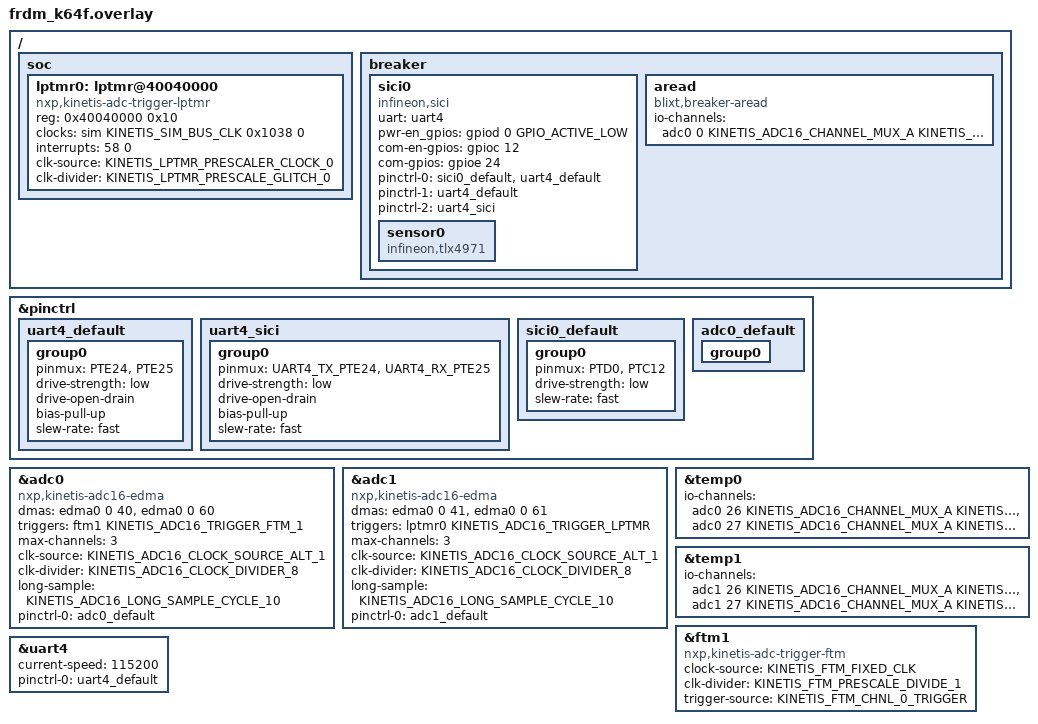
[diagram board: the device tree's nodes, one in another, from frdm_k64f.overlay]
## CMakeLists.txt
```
cmake_minimum_required(VERSION 3.20.0)

find_package(Zephyr REQUIRED HINTS $ENV{ZEPHYR_BASE})

project(tli4971)
add_subdirectory(src)
```

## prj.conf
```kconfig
# Heap and stack size settings
CONFIG_HEAP_MEM_POOL_SIZE=2048
CONFIG_MAIN_STACK_SIZE=2048
CONFIG_SYSTEM_WORKQUEUE_STACK_SIZE=2048

# Stack analysis settings
CONFIG_STACK_SENTINEL=y
CONFIG_STACK_USAGE=y
CONFIG_INIT_STACKS=y

# Thread settings
CONFIG_THREAD_MONITOR=n
CONFIG_THREAD_NAME=y

# Shells
CONFIG_SHELL=y
CONFIG_ADC_SHELL=n
CONFIG_KERNEL_SHELL=y
CONFIG_DEVICE_SHELL=y
CONFIG_SHELL_BACKENDS=y

# Network settings
CONFIG_NETWORKING=y
CONFIG_NET_LOG=y
CONFIG_NET_IPV6=n
CONFIG_NET_IPV4=y
CONFIG_NET_DHCPV4=y
CONFIG_NET_UDP=y
CONFIG_NET_TCP=y
CONFIG_NET_STATISTICS=y
CONFIG_NET_SOCKETS=y
CONFIG_NET_SOCKETS_POSIX_NAMES=y
CONFIG_NET_CONNECTION_MANAGER=y
CONFIG_NET_MGMT=y
CONFIG_NET_MGMT_EVENT=y
CONFIG_NET_CONFIG_AUTO_INIT=n
CONFIG_NET_SHELL=y
CONFIG_NET_MAX_CONN=10

# MCU manager settings
CONFIG_MCUMGR=y
CONFIG_MCUMGR_GRP_IMG=y
CONFIG_MCUMGR_GRP_OS=y
CONFIG_MCUMGR_TRANSPORT_UDP=y
CONFIG_MCUMGR_TRANSPORT_UDP_IPV4=y
CONFIG_MCUMGR_TRANSPORT_UDP_IPV6=n

# CoAP settings
CONFIG_COAP=y
CONFIG_COAP_WELL_KNOWN_BLOCK_WISE=n

# Other settings
CONFIG_PRINTK=y
CONFIG_LOG=y
CONFIG_BOOT_BANNER=y
CONFIG_FLASH=y
CONFIG_BOOTLOADER_MCUBOOT=y

CONFIG_NEWLIB_LIBC=y
CONFIG_CMSIS_DSP=y
CONFIG_CMSIS_DSP_FASTMATH=y

CONFIG_NANOPB=y
CONFIG_ZERO_CONTROL_MESSAGES=y

CONFIG_TIMING_FUNCTIONS=y

# Additional drivers
CONFIG_SICI=y
CONFIG_TLX4971=y
CONFIG_TLX4971_SHELL=y
```

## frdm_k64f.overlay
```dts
#include <dt-bindings/adc/kinetis-adc.h>
#include <dt-bindings/timer/kinetis-lptmr.h>
#include <dt-bindings/timer/kinetis-ftm.h>

/ {
	soc {
		/* LPTMR is not in nxp_k6x.dtsi. */
		lptmr0: lptmr@40040000 {
			compatible = "nxp,kinetis-adc-trigger-lptmr";
			reg = <0x40040000 0x10>;
			clocks = <&sim KINETIS_SIM_BUS_CLK 0x1038 0>;
			interrupts = <58 0>;
			clk-source = <KINETIS_LPTMR_PRESCALER_CLOCK_0>; /* MCGIRCLK */
			clk-divider = <KINETIS_LPTMR_PRESCALE_GLITCH_0>; /* divide by 2 */
			#trigger-cells = <1>;
		};
	};

	breaker {
		sici0: sici0 {
			compatible = "infineon,sici";
			uart = <&uart4>;
			pwr-en_gpios = <&gpiod 0 GPIO_ACTIVE_LOW>;
			com-en-gpios = <&gpioc 12 GPIO_ACTIVE_HIGH>;
			com-gpios = <&gpioe 24 GPIO_ACTIVE_HIGH>;
			pinctrl-0 = <&sici0_default &uart4_default>;
			pinctrl-1 = <&uart4_default>;
			pinctrl-2 = <&uart4_sici>;
			pinctrl-names = "default", "activation", "communication";
			status = "okay";

			sensor0: sensor0 {
				compatible = "infineon,tlx4971";
				status = "okay";
			};
		};

		aread: aread {
			compatible = "blixt,breaker-aread";
			io-channels = <&adc0 0 KINETIS_ADC16_CHANNEL_MUX_A KINETIS_ADC16_CHANNEL_TYPE_DF>; /* I_MAINS */
			io-channel-names = "I_MAINS";
		};
	};
};

&pinctrl {
	uart4_default: uart4_default {
		group0 {
			pinmux = <PTE24>,
				<PTE25>;
			drive-strength = "low";
			drive-open-drain;
			bias-pull-up;
			slew-rate = "fast";
		};
	};

	uart4_sici: uart4_sici {
		group0 {
			pinmux = <UART4_TX_PTE24>,
				<UART4_RX_PTE25>;
			drive-strength = "low";
			drive-open-drain;
			bias-pull-up;
			slew-rate = "fast";
		};
	};

	sici0_default: sici0_default {
		group0 {
			pinmux = <PTD0>,	/* Power pin */
				<PTC12>;	/* Communication enable pin */
			drive-strength = "low";
			slew-rate = "fast";
		};
	};

	adc0_default: adc0_default {
		group0 {
			/* ADC0_DM0/ADC1_DM3 and ADC0_DP0/ADC1_DP3 pins are connected 
			   to ADC0 by detault.
			 */
		};
	};
};

&adc0 {
	compatible = "nxp,kinetis-adc16-edma";
	dmas = <&edma0 0 40>, <&edma0 0 60>; /* Format: <dma_instance, multiplexer, source> */
	dma-names = "RESULT", "CHANNEL";
	triggers = <&ftm1 KINETIS_ADC16_TRIGGER_FTM_1>;
	max-channels = <3>;
	clk-source = <KINETIS_ADC16_CLOCK_SOURCE_ALT_1>;
	clk-divider = <KINETIS_ADC16_CLOCK_DIVIDER_8>;
	long-sample = <KINETIS_ADC16_LONG_SAMPLE_CYCLE_10>;
	pinctrl-0 = <&adc0_default>;
	pinctrl-names = "default";
	status = "okay";
	#io-channel-cells = <3>;
};

&adc1 {
	compatible = "nxp,kinetis-adc16-edma";
	dmas = <&edma0 0 41>, <&edma0 0 61>; /* Format: <dma_instance, multiplexer, source> */
	dma-names = "RESULT", "CHANNEL";
	triggers = <&lptmr0 KINETIS_ADC16_TRIGGER_LPTMR>;
	max-channels = <3>;
	clk-source = <KINETIS_ADC16_CLOCK_SOURCE_ALT_1>;
	clk-divider = <KINETIS_ADC16_CLOCK_DIVIDER_8>;
	long-sample = <KINETIS_ADC16_LONG_SAMPLE_CYCLE_10>;
	pinctrl-0 = <&adc1_default>;
	pinctrl-names = "default";
	status = "okay";
	#io-channel-cells = <3>;
};


&temp0 {
	io-channels = <&adc0 26 KINETIS_ADC16_CHANNEL_MUX_A KINETIS_ADC16_CHANNEL_TYPE_SE>,
		<&adc0 27 KINETIS_ADC16_CHANNEL_MUX_A KINETIS_ADC16_CHANNEL_TYPE_SE>;
	io-channel-names = "SENSOR", "BANDGAP";
};


&temp1 {
	io-channels = <&adc1 26 KINETIS_ADC16_CHANNEL_MUX_A KINETIS_ADC16_CHANNEL_TYPE_SE>,
		<&adc1 27 KINETIS_ADC16_CHANNEL_MUX_A KINETIS_ADC16_CHANNEL_TYPE_SE>;
	io-channel-names = "SENSOR", "BANDGAP";
};


&ftm1 {
	compatible = "nxp,kinetis-adc-trigger-ftm";
	clock-source = <KINETIS_FTM_FIXED_CLK>;
	clk-divider = <KINETIS_FTM_PRESCALE_DIVIDE_1>;
	trigger-source = <KINETIS_FTM_CHNL_0_TRIGGER>;
	#trigger-cells = <1>;
	status = "okay";
};

&lptmr0 {
	status = "okay";
};

&uart4 {
	current-speed = <115200>;
	pinctrl-0 = <&uart4_default>;
	pinctrl-names = "default";
	status = "okay";
};
```

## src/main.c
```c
#include <zephyr/kernel.h>

#ifdef CONFIG_MCUMGR_CMD_IMG_MGMT
#include "img_mgmt/img_mgmt.h"
#endif

#include "networking.h"
#include "services.h"

#include <zephyr/logging/log.h>
LOG_MODULE_REGISTER(main);

void main(void)
{
	LOG_INF("app: zero, built: " __DATE__ " " __TIME__);
	LOG_INF("board: " CONFIG_BOARD);

#ifdef CONFIG_MCUMGR_CMD_IMG_MGMT
	{
		int r;
		struct image_version version;
		r = img_mgmt_my_version(&version);
		if (!r) {
			LOG_INF("version: %" PRIu8 ".%" PRIu8 ".%" PRIu16 " (%" PRIu32 ")",
				version.iv_major, version.iv_minor, version.iv_revision,
				version.iv_build_num);
		} else {
			LOG_WRN("cannot get version");
		}
	}
#endif

	networking_init();
	services_init();

	while (1) {
		k_sleep(K_MSEC(1000));
	}
}
```

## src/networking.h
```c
#ifndef _NETWORKING_H_
#define _NETWORKING_H_

int networking_init(void);

#endif // _NETWORKING_H_
```

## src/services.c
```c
#include "services.h"

#include <zephyr/kernel.h>

#ifdef CONFIG_MCUMGR_SMP_UDP
#include <zephyr/mgmt/mcumgr/smp_udp.h>
#endif

#ifdef CONFIG_MCUMGR_CMD_OS_MGMT
#include "os_mgmt/os_mgmt.h"
#endif
#ifdef CONFIG_MCUMGR_CMD_IMG_MGMT
#include "img_mgmt/img_mgmt.h"
#endif

#include <zephyr/logging/log.h>
LOG_MODULE_REGISTER(services);

int services_init(void)
{
#ifdef CONFIG_MCUMGR_CMD_OS_MGMT
	os_mgmt_register_group();
#endif

#ifdef CONFIG_MCUMGR_CMD_IMG_MGMT
	img_mgmt_register_group();
#endif

#ifdef CONFIG_MCUMGR_SMP_UDP
	{
		int r = smp_udp_open();
		if (r < 0) {
			LOG_ERR("Cannot not open smp udp %d", r);
			return r;
		}
	}
#endif

	return 0;
}
```
